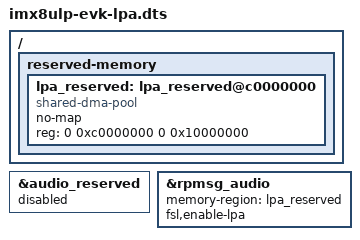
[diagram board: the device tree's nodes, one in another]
// SPDX-License-Identifier: (GPL-2.0+ OR MIT)
/*
 * Copyright 2022 NXP
 */

#include "imx8ulp-evk.dts"
/ {
    reserved-memory {
        lpa_reserved: lpa_reserved@c0000000 {
            compatible = "shared-dma-pool";
            no-map;
            reg = <0 0xc0000000 0 0x10000000>;
        };
    };
};

&audio_reserved {
    status = "disabled";
};

&rpmsg_audio {
    memory-region = <&lpa_reserved>;
    fsl,enable-lpa;
};
